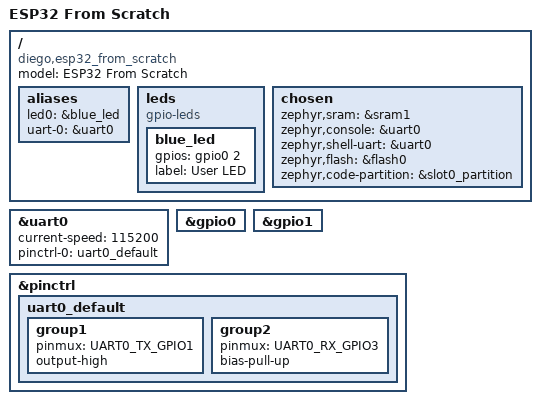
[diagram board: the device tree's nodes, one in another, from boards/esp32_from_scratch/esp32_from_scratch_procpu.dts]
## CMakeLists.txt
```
cmake_minimum_required(VERSION 3.20.0)

list(APPEND BOARD_ROOT ${CMAKE_CURRENT_SOURCE_DIR})
find_package(Zephyr REQUIRED)
project(my_zephyr_app)

target_sources(app PRIVATE src/main.cpp)

add_subdirectory(drivers/diego_led)
```

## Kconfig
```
config APP_HEARTBEAT_PERIOD_MS
	int "app heartbeat (ms)"
	default 2000
	range 100 2000

menuconfig LED_SUBSYSTEM
	bool "LED Subsystem"
	default y
if LED_SUBSYSTEM

choice
	prompt "LED Blink Sleep Time"
	default BLINK_SLEEP_1000MS

config BLINK_SLEEP_250MS
	bool "Fast (250ms)"
 
config BLINK_SLEEP_1000MS
	bool "Medium (1s)"
 
config BLINK_SLEEP_2000MS
	bool "Slow (2s)"
endchoice

config BLINK_SLEEP_TIME_MS
	int
	default 250 if BLINK_SLEEP_250MS
	default 1000 if BLINK_SLEEP_1000MS
	default 2000 if BLINK_SLEEP_2000MS
	default 0


menuconfig LED_ADVANCED
	bool "Advanced LED Settings"
	default n
if LED_ADVANCED

config LED_BRIGHTNESS
	int "LED Brightness (0-100)"
	range 0 100
	default 100

config LED_FADE_DURATION_MS
	int "LED Fade Duration (ms)"
	range 0 5000
	default 500
menu "Expert Settings"

config LED_DEBUG
	bool "Enable LED Debugging"

config LED_CUSTOM_BLINK_PATTERN
	bool "Custom Blink Pattern"

endmenu
endif #LED_ADVANCED
endif #LED_SUBSYSTEM



source "Kconfig.zephyr"
rsource "drivers/diego_led/Kconfig"
```

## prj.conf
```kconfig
CONFIG_GPIO=y
CONFIG_LOG=y
CONFIG_DIEGO_LED=y
CONFIG_SHELL=y
```

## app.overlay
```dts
/{
	aliases {
		app-led = &blue_led;
	};

	leds {
		compatible = "gpio-leds"; 
		
		red_led: red_led {
			gpios = < &gpio0 0x4 0x0 >;
			label = "External LED";
		};
	};

	diego_led0: diego_led{
		compatible = "diego,led";
		status = "okay";
	};
};
```

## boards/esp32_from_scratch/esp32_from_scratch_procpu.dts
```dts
/dts-v1/;

#include <espressif/esp32/esp32_wroom_32ue_n4.dtsi>
#include <zephyr/dt-bindings/input/input-event-codes.h>
#include <espressif/partitions_0x1000_amp.dtsi>
#include <zephyr/dt-bindings/pinctrl/esp-pinctrl-common.h>
#include <zephyr/dt-bindings/pinctrl/esp32-pinctrl.h>
#include <zephyr/dt-bindings/pinctrl/esp32-gpio-sigmap.h>


/ {
	model = "ESP32 From Scratch";
	compatible = "diego,esp32_from_scratch";

	aliases {
		led0 = &blue_led;
		uart-0 = &uart0;
	};

	leds {
		compatible = "gpio-leds";

		blue_led: blue_led {
			gpios = <&gpio0 2 GPIO_ACTIVE_HIGH>;
			label = "User LED";
		};
	};

	chosen {
		zephyr,sram = &sram1;
		zephyr,console = &uart0;
		zephyr,shell-uart = &uart0;
		zephyr,flash = &flash0;
		zephyr,code-partition = &slot0_partition;
	};
};

&uart0 {
	status = "okay";
	current-speed = <115200>;
	pinctrl-0 = <&uart0_default>;
	pinctrl-names = "default";
};

&gpio0 {
	status = "okay";
};

&gpio1 {
	status = "okay";
};

&pinctrl {
	uart0_default: uart0_default {
		group1 {
			pinmux = <UART0_TX_GPIO1>;
			output-high;
		};

		group2 {
			pinmux = <UART0_RX_GPIO3>;
			bias-pull-up;
		};
	};
};
```

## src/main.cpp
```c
#include <zephyr/drivers/gpio.h>
#include <zephyr/kernel.h>
#include <zephyr/logging/log.h>
#include <zephyr/drivers/sensor.h>
#include "../includes/diego_led.h"

/* The devicetree node identifier for the "led0" alias. */
/* now use a app_led alias for led0*/
#define LED_NODE DT_ALIAS(app_led)
static const struct gpio_dt_spec led = GPIO_DT_SPEC_GET(LED_NODE, gpios);
const struct device *dev = DEVICE_DT_GET(DT_NODELABEL(diego_led0));
struct sensor_value val;

LOG_MODULE_REGISTER(main, LOG_LEVEL_INF);

namespace {
	void test() {
		int ret = sensor_channel_get(dev, SENSOR_CHAN_AMBIENT_TEMP, &val);
		LOG_INF("Channel ret %d", ret);
		k_msleep(CONFIG_APP_HEARTBEAT_PERIOD_MS);
		ret = sensor_sample_fetch(dev);
		k_msleep(CONFIG_APP_HEARTBEAT_PERIOD_MS);
		ret = sensor_channel_get(dev, SENSOR_CHAN_AMBIENT_TEMP, &val);
		diego_led_set_valor(dev, 100);
	}
}

int main(void)
{
      
    bool led_state = true;

    if (!gpio_is_ready_dt(&led)) return 0;

    if (gpio_pin_configure_dt(&led, GPIO_OUTPUT_ACTIVE) < 0) return 0;

    test();

    while (1) {
        if (gpio_pin_toggle_dt(&led) < 0) return 0;

        led_state = !led_state;
        LOG_INF("LED state: %s", led_state ? "ON" : "OFF");
        k_msleep(CONFIG_APP_HEARTBEAT_PERIOD_MS);
    }
    return 0;
}
```
